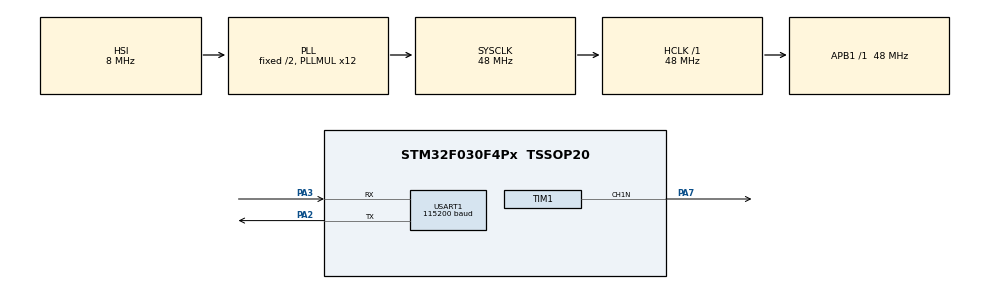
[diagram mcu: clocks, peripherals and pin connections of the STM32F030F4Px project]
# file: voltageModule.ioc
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Dma.Request0=USART1_RX
Dma.USART1_RX.0.Direction=DMA_PERIPH_TO_MEMORY
Dma.USART1_RX.0.Instance=DMA1_Channel5
Dma.USART1_RX.0.MemDataAlignment=DMA_MDATAALIGN_BYTE
Dma.USART1_RX.0.MemInc=DMA_MINC_ENABLE
Dma.USART1_RX.0.Mode=DMA_NORMAL
Dma.USART1_RX.0.PeriphDataAlignment=DMA_PDATAALIGN_BYTE
Dma.USART1_RX.0.PeriphInc=DMA_PINC_DISABLE
Dma.USART1_RX.0.Priority=DMA_PRIORITY_LOW
Mcu.Family=STM32F0
Mcu.Name=STM32F030F4Px
Mcu.Package=TSSOP20
NVIC.DMA1_Channel4_5_IRQn=true\:3\:0\:true\:false\:true\:false\:true\:true
NVIC.TIM3_IRQn=true\:0\:0\:true\:false\:true\:true\:true\:true
PA13.Mode=Serial_Wire
PA13.Signal=SYS_SWDIO
PA14.Mode=Serial_Wire
PA14.Signal=SYS_SWCLK
PA2.Mode=Asynchronous
PA2.Signal=USART1_TX
PA3.Mode=Asynchronous
PA3.Signal=USART1_RX
PA7.Mode=PWM Generation1 CH1N
PA7.Signal=TIM1_CH1N
ProjectManager.HeapSize=0x200
ProjectManager.StackSize=0x400
ProjectManager.TargetToolchain=EWARM V7
RCC.AHBFreq_Value=48000000
RCC.APB1Freq_Value=48000000
RCC.APB1TimFreq_Value=48000000
RCC.HCLKFreq_Value=48000000
RCC.PLLMUL=RCC_PLL_MUL12
RCC.SYSCLKFreq_VALUE=48000000
RCC.SYSCLKSource=RCC_SYSCLKSOURCE_PLLCLK
TIM1.Channel-PWM\ Generation1\ CH1N=TIM_CHANNEL_1
TIM1.Period=255
TIM3.Channel-Output\ Compare1\ No\ Output=TIM_CHANNEL_1
TIM3.Period=375
USART1.BaudRate=115200
USART1.VirtualMode-Asynchronous=VM_ASYNC
VP_TIM1_VS_ClockSourceINT.Mode=Internal
VP_TIM3_VS_ClockSourceINT.Mode=Internal
VP_TIM3_VS_no_output1.Mode=Output Compare1 No Output
board=custom

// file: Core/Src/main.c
/* USER CODE BEGIN Header */
/**
  ******************************************************************************
  * @file           : main.c
  * @brief          : Main program body
  ******************************************************************************
  * @attention
  *
  * Copyright (c) 2024 STMicroelectronics.
  * All rights reserved.
  *
  * This software is licensed under terms that can be found in the LICENSE file
  * in the root directory of this software component.
  * If no LICENSE file comes with this software, it is provided AS-IS.
  *
  ******************************************************************************
  */
/* USER CODE END Header */
#include "main.h"
#include "dma.h"
#include "tim.h"
#include "usart.h"
#include "gpio.h"

void SystemClock_Config(void);

/* USER CODE BEGIN 0 */
uint16_t sig;
/* USER CODE END 0 */

int main(void)
{

  /* MCU Configuration--------------------------------------------------------*/

  /* Reset of all peripherals, Initializes the Flash interface and the Systick. */
  HAL_Init();

  /* Configure the system clock */
  SystemClock_Config();

  /* Initialize all configured peripherals */
  MX_GPIO_Init();
  MX_DMA_Init();
  MX_USART1_UART_Init();
  MX_TIM3_Init();
  MX_TIM1_Init();
  /* USER CODE BEGIN 2 */
	SignalInit();
	HAL_TIM_Base_Start_IT(&htim3);
	HAL_TIM_PWM_Start_DMA(&htim1, TIM_CHANNEL_1, (uint32_t*) &sig, 1);
//	HAL_SPI_Transmit_DMA(&hspi1, (uint8_t*) GetSignal(), 1);
  /* USER CODE END 2 */

  /* Infinite loop */
  while (1)
  {

  }
}

void SystemClock_Config(void)
{
  RCC_OscInitTypeDef RCC_OscInitStruct = {0};
  RCC_ClkInitTypeDef RCC_ClkInitStruct = {0};
  RCC_PeriphCLKInitTypeDef PeriphClkInit = {0};

  /** Initializes the RCC Oscillators according to the specified parameters
  * in the RCC_OscInitTypeDef structure.
  */
  RCC_OscInitStruct.OscillatorType = RCC_OSCILLATORTYPE_HSI;
  RCC_OscInitStruct.HSIState = RCC_HSI_ON;
  RCC_OscInitStruct.HSICalibrationValue = RCC_HSICALIBRATION_DEFAULT;
  RCC_OscInitStruct.PLL.PLLState = RCC_PLL_ON;
  RCC_OscInitStruct.PLL.PLLSource = RCC_PLLSOURCE_HSI;
  RCC_OscInitStruct.PLL.PLLMUL = RCC_PLL_MUL12;
  RCC_OscInitStruct.PLL.PREDIV = RCC_PREDIV_DIV1;
  if (HAL_RCC_OscConfig(&RCC_OscInitStruct) != HAL_OK)
  {
    Error_Handler();
  }

  /** Initializes the CPU, AHB and APB buses clocks
  */
  RCC_ClkInitStruct.ClockType = RCC_CLOCKTYPE_HCLK|RCC_CLOCKTYPE_SYSCLK
                              |RCC_CLOCKTYPE_PCLK1;
  RCC_ClkInitStruct.SYSCLKSource = RCC_SYSCLKSOURCE_PLLCLK;
  RCC_ClkInitStruct.AHBCLKDivider = RCC_SYSCLK_DIV1;
  RCC_ClkInitStruct.APB1CLKDivider = RCC_HCLK_DIV1;

  if (HAL_RCC_ClockConfig(&RCC_ClkInitStruct, FLASH_LATENCY_1) != HAL_OK)
  {
    Error_Handler();
  }
  PeriphClkInit.PeriphClockSelection = RCC_PERIPHCLK_USART1;
  PeriphClkInit.Usart1ClockSelection = RCC_USART1CLKSOURCE_PCLK1;
  if (HAL_RCCEx_PeriphCLKConfig(&PeriphClkInit) != HAL_OK)
  {
    Error_Handler();
  }
}

/* USER CODE BEGIN 4 */
void HAL_TIM_PeriodElapsedCallback(TIM_HandleTypeDef* htim)
{
    sig = GetNext();
}
/* USER CODE END 4 */

void Error_Handler(void)
{
  __disable_irq();
  while (1)
  {
  }
}
